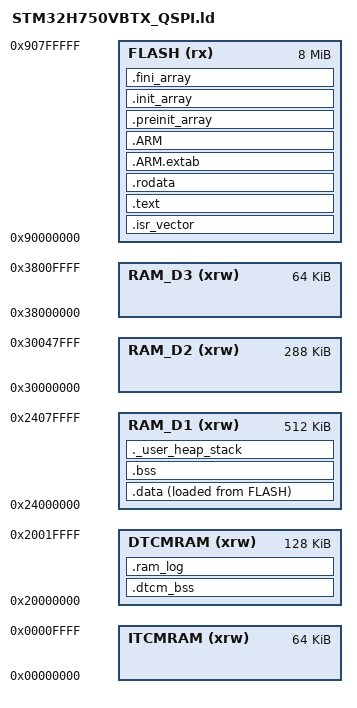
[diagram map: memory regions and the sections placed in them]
/*
******************************************************************************
**
**  File        : LinkerScript.ld
**
**  Author      : STM32CubeIDE
**
**  Abstract    : Linker script for STM32H7 series
**                128Kbytes FLASH and 1056Kbytes RAM
**
**                Set heap size, stack size and stack location according
**                to application requirements.
**
**                Set memory bank area and size if external memory is used.
**
**  Target      : STMicroelectronics STM32
**
**  Distribution: The file is distributed as is, without any warranty
**                of any kind.
**
*****************************************************************************
** @attention
**
** Copyright (c) 2026 STMicroelectronics.
** All rights reserved.
**
** This software is licensed under terms that can be found in the LICENSE file
** in the root directory of this software component.
** If no LICENSE file comes with this software, it is provided AS-IS.
**
****************************************************************************
*/

/* Entry Point */
ENTRY(Reset_Handler)

/* Highest address of the user mode stack */
/* Stack top pulled 8 bytes below end of RAM_D1: the WeAct ExtMem_Boot_USB
   bootloader validates the app's initial SP with (SP & 0x2FF80000) == 0x24000000,
   which rejects the exact end-of-RAM value 0x24080000. */
_estack = ORIGIN(RAM_D1) + LENGTH(RAM_D1) - 8;
/* Generate a link error if heap and stack don't fit into RAM */
_Min_Heap_Size = 0x800;      /* required amount of heap  */
_Min_Stack_Size = 0x800; /* required amount of stack */

/* Specify the memory areas */
MEMORY
{
  FLASH (rx)     : ORIGIN = 0x90000000, LENGTH = 8192K
  DTCMRAM (xrw)  : ORIGIN = 0x20000000, LENGTH = 128K
  RAM_D1 (xrw)   : ORIGIN = 0x24000000, LENGTH = 512K
  RAM_D2 (xrw)   : ORIGIN = 0x30000000, LENGTH = 288K
  RAM_D3 (xrw)   : ORIGIN = 0x38000000, LENGTH = 64K
  ITCMRAM (xrw)  : ORIGIN = 0x00000000, LENGTH = 64K
}

/* Define output sections */
SECTIONS
{
  /* The startup code goes first into FLASH */
  .isr_vector :
  {
    . = ALIGN(4);
    KEEP(*(.isr_vector)) /* Startup code */
    . = ALIGN(4);
  } >FLASH

  /* The program code and other data goes into FLASH */
  .text :
  {
    . = ALIGN(4);
    *(.text)           /* .text sections (code) */
    *(.text*)          /* .text* sections (code) */
    *(.glue_7)         /* glue arm to thumb code */
    *(.glue_7t)        /* glue thumb to arm code */
    *(.eh_frame)

    KEEP (*(.init))
    KEEP (*(.fini))

    . = ALIGN(4);
    _etext = .;        /* define a global symbols at end of code */
  } >FLASH

  /* Constant data goes into FLASH */
  .rodata :
  {
    . = ALIGN(4);
    *(.rodata)         /* .rodata sections (constants, strings, etc.) */
    *(.rodata*)        /* .rodata* sections (constants, strings, etc.) */
    . = ALIGN(4);
  } >FLASH

  .ARM.extab (READONLY) : /* The READONLY keyword is only supported in GCC11 and later, remove it if using GCC10 or earlier. */
  {
    *(.ARM.extab* .gnu.linkonce.armextab.*)
  } >FLASH
  .ARM (READONLY) : /* The READONLY keyword is only supported in GCC11 and later, remove it if using GCC10 or earlier. */
  {
    __exidx_start = .;
    *(.ARM.exidx*)
    __exidx_end = .;
  } >FLASH

  .preinit_array (READONLY) : /* The READONLY keyword is only supported in GCC11 and later, remove it if using GCC10 or earlier. */
  {
    PROVIDE_HIDDEN (__preinit_array_start = .);
    KEEP (*(.preinit_array*))
    PROVIDE_HIDDEN (__preinit_array_end = .);
  } >FLASH

  .init_array (READONLY) : /* The READONLY keyword is only supported in GCC11 and later, remove it if using GCC10 or earlier. */
  {
    PROVIDE_HIDDEN (__init_array_start = .);
    KEEP (*(SORT(.init_array.*)))
    KEEP (*(.init_array*))
    PROVIDE_HIDDEN (__init_array_end = .);
  } >FLASH

  .fini_array (READONLY) : /* The READONLY keyword is only supported in GCC11 and later, remove it if using GCC10 or earlier. */
  {
    PROVIDE_HIDDEN (__fini_array_start = .);
    KEEP (*(SORT(.fini_array.*)))
    KEEP (*(.fini_array*))
    PROVIDE_HIDDEN (__fini_array_end = .);
  } >FLASH

  /* used by the startup to initialize data */
  _sidata = LOADADDR(.data);

  /* Initialized data sections goes into RAM, load LMA copy after code */
  .data :
  {
    . = ALIGN(4);
    _sdata = .;        /* create a global symbol at data start */
    *(.data)           /* .data sections */
    *(.data*)          /* .data* sections */
    *(.RamFunc)        /* .RamFunc sections */
    *(.RamFunc*)       /* .RamFunc* sections */

    . = ALIGN(4);
    _edata = .;        /* define a global symbol at data end */
  } >RAM_D1 AT> FLASH

  /* Uninitialized data section */
  . = ALIGN(4);
  .bss :
  {
    /* This is used by the startup in order to initialize the .bss section */
    _sbss = .;         /* define a global symbol at bss start */
    __bss_start__ = _sbss;
    *(.bss)
    *(.bss*)
    *(COMMON)

    . = ALIGN(4);
    _ebss = .;         /* define a global symbol at bss end */
    __bss_end__ = _ebss;
  } >RAM_D1

  /* Kestrel: gate grayscale buffers live in DTCM (fast, CPU-only,
   * retained across STOP mode). */
  .dtcm_bss (NOLOAD) :
  {
    . = ALIGN(4);
    *(.dtcm_bss)
    *(.dtcm_bss*)
    . = ALIGN(4);
  } >DTCMRAM

  /* Kestrel: in-RAM log capture. DTCM: always clocked (no RCC gate),
   * retained through reset, readable by the ROM bootloader -> dump via
   * DFU memory read. Lands right after the gate buffers (~0x20009600). */
  .ram_log (NOLOAD) :
  {
    . = ALIGN(4);
    *(.ram_log)
    *(.ram_log*)
  } >DTCMRAM

  /* User_heap_stack section, used to check that there is enough RAM left */
  ._user_heap_stack :
  {
    . = ALIGN(8);
    PROVIDE ( end = . );
    PROVIDE ( _end = . );
    . = . + _Min_Heap_Size;
    . = . + _Min_Stack_Size;
    . = ALIGN(8);
  } >RAM_D1

  /* Remove information from the standard libraries */
  /DISCARD/ :
  {
    libc.a ( * )
    libm.a ( * )
    libgcc.a ( * )
  }

  .ARM.attributes 0 : { *(.ARM.attributes) }
}


